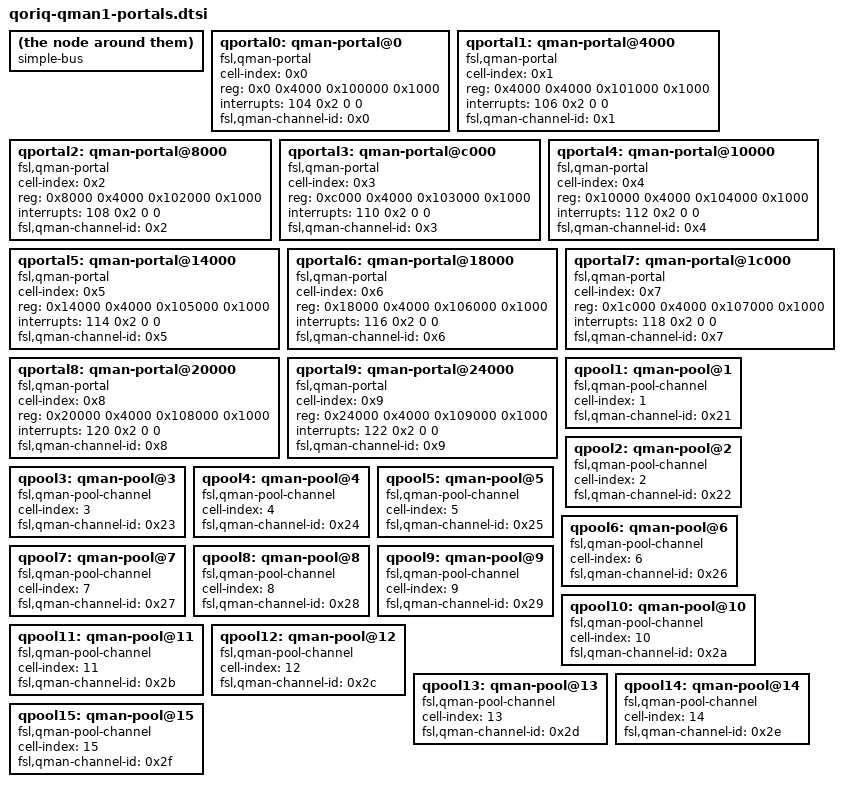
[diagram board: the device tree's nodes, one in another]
/*
 * QorIQ QMan Portal device tree stub for 10 portals & 15 pool channels
 *
 * Copyright 2011 Freescale Semiconductor Inc.
 *
 * Redistribution and use in source and binary forms, with or without
 * modification, are permitted provided that the following conditions are met:
 *     * Redistributions of source code must retain the above copyright
 *       notice, this list of conditions and the following disclaimer.
 *     * Redistributions in binary form must reproduce the above copyright
 *       notice, this list of conditions and the following disclaimer in the
 *       documentation and/or other materials provided with the distribution.
 *     * Neither the name of Freescale Semiconductor nor the
 *       names of its contributors may be used to endorse or promote products
 *       derived from this software without specific prior written permission.
 *
 *
 * ALTERNATIVELY, this software may be distributed under the terms of the
 * GNU General Public License ("GPL") as published by the Free Software
 * Foundation, either version 2 of that License or (at your option) any
 * later version.
 *
 * THIS SOFTWARE IS PROVIDED BY Freescale Semiconductor ``AS IS'' AND ANY
 * EXPRESS OR IMPLIED WARRANTIES, INCLUDING, BUT NOT LIMITED TO, THE IMPLIED
 * WARRANTIES OF MERCHANTABILITY AND FITNESS FOR A PARTICULAR PURPOSE ARE
 * DISCLAIMED. IN NO EVENT SHALL Freescale Semiconductor BE LIABLE FOR ANY
 * DIRECT, INDIRECT, INCIDENTAL, SPECIAL, EXEMPLARY, OR CONSEQUENTIAL DAMAGES
 * (INCLUDING, BUT NOT LIMITED TO, PROCUREMENT OF SUBSTITUTE GOODS OR SERVICES;
 * LOSS OF USE, DATA, OR PROFITS; OR BUSINESS INTERRUPTION) HOWEVER CAUSED AND
 * ON ANY THEORY OF LIABILITY, WHETHER IN CONTRACT, STRICT LIABILITY, OR TORT
 * (INCLUDING NEGLIGENCE OR OTHERWISE) ARISING IN ANY WAY OUT OF THE USE OF THIS
 * SOFTWARE, EVEN IF ADVISED OF THE POSSIBILITY OF SUCH DAMAGE.
 */

#address-cells = <0x1>;
#size-cells = <0x1>;
compatible = "simple-bus";
qportal0: qman-portal@0 {
	cell-index = <0x0>;
	compatible = "fsl,qman-portal";
	reg = <0x0 0x4000 0x100000 0x1000>;
	interrupts = <104 0x2 0 0>;
	fsl,qman-channel-id = <0x0>;
};

qportal1: qman-portal@4000 {
	cell-index = <0x1>;
	compatible = "fsl,qman-portal";
	reg = <0x4000 0x4000 0x101000 0x1000>;
	interrupts = <106 0x2 0 0>;
	fsl,qman-channel-id = <0x1>;
};

qportal2: qman-portal@8000 {
	cell-index = <0x2>;
	compatible = "fsl,qman-portal";
	reg = <0x8000 0x4000 0x102000 0x1000>;
	interrupts = <108 0x2 0 0>;
	fsl,qman-channel-id = <0x2>;
};

qportal3: qman-portal@c000 {
	cell-index = <0x3>;
	compatible = "fsl,qman-portal";
	reg = <0xc000 0x4000 0x103000 0x1000>;
	interrupts = <110 0x2 0 0>;
	fsl,qman-channel-id = <0x3>;
};

qportal4: qman-portal@10000 {
	cell-index = <0x4>;
	compatible = "fsl,qman-portal";
	reg = <0x10000 0x4000 0x104000 0x1000>;
	interrupts = <112 0x2 0 0>;
	fsl,qman-channel-id = <0x4>;
};

qportal5: qman-portal@14000 {
	cell-index = <0x5>;
	compatible = "fsl,qman-portal";
	reg = <0x14000 0x4000 0x105000 0x1000>;
	interrupts = <114 0x2 0 0>;
	fsl,qman-channel-id = <0x5>;
};

qportal6: qman-portal@18000 {
	cell-index = <0x6>;
	compatible = "fsl,qman-portal";
	reg = <0x18000 0x4000 0x106000 0x1000>;
	interrupts = <116 0x2 0 0>;
	fsl,qman-channel-id = <0x6>;
};

qportal7: qman-portal@1c000 {
	cell-index = <0x7>;
	compatible = "fsl,qman-portal";
	reg = <0x1c000 0x4000 0x107000 0x1000>;
	interrupts = <118 0x2 0 0>;
	fsl,qman-channel-id = <0x7>;
};

qportal8: qman-portal@20000 {
	cell-index = <0x8>;
	compatible = "fsl,qman-portal";
	reg = <0x20000 0x4000 0x108000 0x1000>;
	interrupts = <120 0x2 0 0>;
	fsl,qman-channel-id = <0x8>;
};

qportal9: qman-portal@24000 {
	cell-index = <0x9>;
	compatible = "fsl,qman-portal";
	reg = <0x24000 0x4000 0x109000 0x1000>;
	interrupts = <122 0x2 0 0>;
	fsl,qman-channel-id = <0x9>;
};

qpool1: qman-pool@1 {
	cell-index = <1>;
	compatible = "fsl,qman-pool-channel";
	fsl,qman-channel-id = <0x21>;
};

qpool2: qman-pool@2 {
	cell-index = <2>;
	compatible = "fsl,qman-pool-channel";
	fsl,qman-channel-id = <0x22>;
};

qpool3: qman-pool@3 {
	cell-index = <3>;
	compatible = "fsl,qman-pool-channel";
	fsl,qman-channel-id = <0x23>;
};

qpool4: qman-pool@4 {
	cell-index = <4>;
	compatible = "fsl,qman-pool-channel";
	fsl,qman-channel-id = <0x24>;
};

qpool5: qman-pool@5 {
	cell-index = <5>;
	compatible = "fsl,qman-pool-channel";
	fsl,qman-channel-id = <0x25>;
};

qpool6: qman-pool@6 {
	cell-index = <6>;
	compatible = "fsl,qman-pool-channel";
	fsl,qman-channel-id = <0x26>;
};

qpool7: qman-pool@7 {
	cell-index = <7>;
	compatible = "fsl,qman-pool-channel";
	fsl,qman-channel-id = <0x27>;
};

qpool8: qman-pool@8 {
	cell-index = <8>;
	compatible = "fsl,qman-pool-channel";
	fsl,qman-channel-id = <0x28>;
};

qpool9: qman-pool@9 {
	cell-index = <9>;
	compatible = "fsl,qman-pool-channel";
	fsl,qman-channel-id = <0x29>;
};

qpool10: qman-pool@10 {
	cell-index = <10>;
	compatible = "fsl,qman-pool-channel";
	fsl,qman-channel-id = <0x2a>;
};

qpool11: qman-pool@11 {
	cell-index = <11>;
	compatible = "fsl,qman-pool-channel";
	fsl,qman-channel-id = <0x2b>;
};

qpool12: qman-pool@12 {
	cell-index = <12>;
	compatible = "fsl,qman-pool-channel";
	fsl,qman-channel-id = <0x2c>;
};

qpool13: qman-pool@13 {
	cell-index = <13>;
	compatible = "fsl,qman-pool-channel";
	fsl,qman-channel-id = <0x2d>;
};

qpool14: qman-pool@14 {
	cell-index = <14>;
	compatible = "fsl,qman-pool-channel";
	fsl,qman-channel-id = <0x2e>;
};

qpool15: qman-pool@15 {
	cell-index = <15>;
	compatible = "fsl,qman-pool-channel";
	fsl,qman-channel-id = <0x2f>;
};
